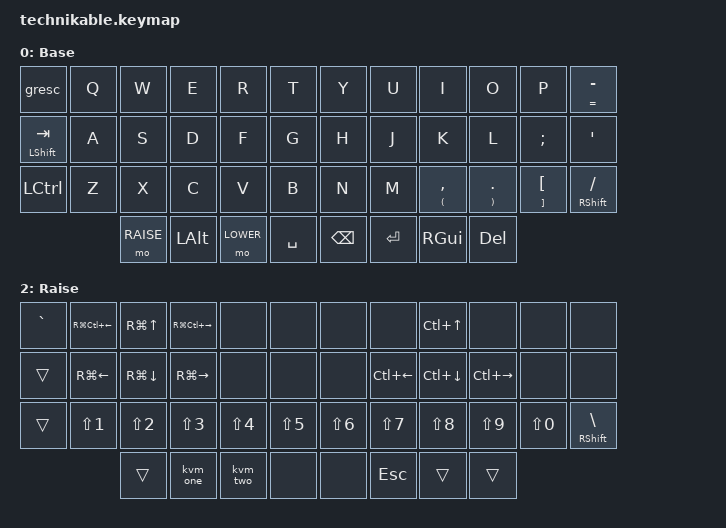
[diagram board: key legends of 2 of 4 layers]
/*
 * Copyright (c) 2022 Pete Johanson
 *
 * SPDX-License-Identifier: MIT
 */

 // build with 
 // west build -b technikable -DZMK_CONFIG="C:\Users\Nick\Documents\github\twiz-technikable"

#include <behaviors.dtsi>
#include <dt-bindings/zmk/keys.h>
#include <dt-bindings/zmk/bt.h>
#include <dt-bindings/zmk/outputs.h>


#define TBLE_ORTHO   true

#define BAS_L  0
#define LOWER  1
#define RAISE  2
#define ADJUST 3

// Using layer taps on thumbs, having quick tap as well helps w/ repeating space/backspace
&lt { quick_tap_ms = <200>; };
&mt { tapping-term-ms = <250>; };

#define BT(n) BT_SEL n

// MAJOR TAB HOLD KEYS
#define ES_TSK  &mt LS(LC(ESC)) ESC
#define COM_PR  &tp LPAR COMMA
#define DOT_PR  &tp RPAR DOT
#define SH_TAB  &tp LSHFT TAB // todo
#define SH_SLS  &tp RSHFT FSLH
#define SH_BSLS &tp RSHFT BSLH
#define ABRC    &tp RBKT LBKT //Brackets (ambidexterous)
#define PLS_MIN &tp EQUAL MINUS

// TAB MANAGEMENT
#define TAB_RES &kp LC(LS(T)) 
#define TABLF1  &mt F1 LC(LS(TAB)) 
#define TABRF3  &mt F3 LC(TAB) 
#define F5CF5   &mt F5 LC(F5)

// WINDOW AND VIRTUAL DESKTOP MANAGEMENT
#define SNAPUP  &kp RG(UP) 
#define SNAPLFT &kp RG(LEFT)
#define SNAPDN  &kp RG(DOWN) 
#define SNAPRGT &kp RG(RIGHT)
#define VDLFT   &kp RG(LC(LEFT)) 
#define VDRGT   &kp RG(LC(RIGHT)) 

// HOLD TAPS WITH NUMBERS AND USEFUL UTILITIES
#define DRK_1    &mt LA(LS(F)) N1  
#define VIS_3    &mt LA(LG(V)) N3 
#define AUDSRC_5 &mt LA(LC(LS(G))) N5  // 6 on tap, toggle audio source on hold
#define SSNIP    &kp LG(LS(S))  // GUI+SHIFT+S for snipping tool

// ADVANCED ALT TAB
/*
#define ALT_TAB &kp G  // todo// alt tab with timeout functionality
#define SHALTAB &kp G  // todo// when held: shift, when tapped: alt tab with timeout functionality
*/

#define MAXIMIZE &kp H // todo
#define AUDIOSRC &kp H // todo
#define PIK_WIN  &kp H // todo
#define VDTVIEW  &kp H // todo

#define TD_RD &kp G  // todo// macro for labelling in gmail
#define WT_SV &kp G  // todo// macro for labelling in gmail


/ {
    chosen {
       zmk,matrix_transform =
                       &ortho_transform;
    };

    conditional_layers {
        compatible = "zmk,conditional-layers";
        tri_layer {
            if-layers = <LOWER RAISE>;
            then-layer = <ADJUST>;
        };
    };
    behaviors {
        gresc: grave_escape {
            compatible = "zmk,behavior-mod-morph";
            label = "GRAVE_ESCAPE";
            #binding-cells = <0>;
            bindings = <ES_TSK>, <&kp GRAVE>;
            mods = <(MOD_RGUI|MOD_LSFT|MOD_LCTL|MOD_RSFT)>;
        };
        tp: tap-preferred {
            compatible = "zmk,behavior-hold-tap";
            label = "TAP_PREFERRED";
            #binding-cells = <2>;
            tapping-term-ms = <150>;
            quick-tap-ms = <0>;
            flavor = "tap-preferred";
            bindings = <&kp>, <&kp>;
        };
    };
    macros {
        link_paste: link_paste {
            label = "link_paste";
            compatible = "zmk,behavior-macro";
            #binding-cells = <0>;
            wait-ms = <50>;
            bindings
                = <&macro_press &kp LCTRL>
                , <&macro_tap &kp K>
                , <&macro_release &kp LCTRL>
                , <&macro_pause_for_release>
                , <&macro_press &kp LCTRL>
                , <&macro_tap &kp V>
                , <&macro_release &kp LCTRL>
                , <&macro_tap &kp ENTER>
                ;
        };
        //KVM SWITCHING
        kvm_one: kvm_one {
            label = "kvm_one";
            compatible = "zmk,behavior-macro";
            #binding-cells = <0>;
            wait-ms = <50>;
            bindings
                = <&macro_tap &kp SCROLLLOCK>
                , <&macro_tap &kp SCROLLLOCK>
                , <&macro_tap &kp N1>
                , <&macro_tap &kp ENTER>
                ;
        };
        kvm_two: kvm_two {
            label = "kvm_two";
            compatible = "zmk,behavior-macro";
            #binding-cells = <0>;
            wait-ms = <50>;
            bindings
                = <&macro_tap &kp SCROLLLOCK>
                , <&macro_tap &kp SCROLLLOCK>
                , <&macro_tap &kp N2>
                , <&macro_tap &kp ENTER>
                ;
        };
    };
    keymap {
        compatible = "zmk,keymap";

        base_layer {
            label = "Base";
            bindings = <
 &gresc      &kp Q      &kp W      &kp E       &kp R          &kp T          &kp Y            &kp U          &kp I       &kp O      &kp P         PLS_MIN
 SH_TAB      &kp A      &kp S      &kp D       &kp F          &kp G          &kp H            &kp J          &kp K       &kp L      &kp SEMI      &kp QUOT
 &kp LCTRL   &kp Z      &kp X      &kp C       &kp V          &kp B          &kp N            &kp M          COM_PR      DOT_PR     ABRC          SH_SLS
                        &mo RAISE  &kp LALT    &mo LOWER      &kp SPACE      &kp BSPC         &kp RET        &kp RGUI    &kp DEL
            >;
        };

        lower {
            label = "Lower";
            bindings = <
TAB_RES    TABLF1       &kp F2        TABRF3        &kp F4       F5CF5        &kp F6        &kp F7       &kp UP       &kp F9       &kp F10      &kp F11
&trans     &kp HOME     &kp PG_DN     &kp PG_UP     &kp END      SSNIP        &none         &kp LEFT     &kp DOWN     &kp RIGHT    &kp F8       &kp F12
&trans     DRK_1        &kp N2        VIS_3   &mt &link_paste N4 AUDSRC_5     &kp N6        &kp N7       &kp N8       &kp N9       &kp N0       SH_BSLS
                        &trans        &trans        &trans       &trans       &trans        &trans       &trans       &kp INS
           >;
        };

        raise {
            label = "Raise";
            bindings = <
&kp GRAVE  VDLFT      SNAPUP       VDRGT         &none          &none      &none         &none          &kp LC(UP)   &none         &none      &none 
&trans     SNAPLFT    SNAPDN       SNAPRGT       &none          &none      &none         &kp LC(LEFT)   &kp LC(DOWN) &kp LC(RIGHT) &none      &none 
&trans     &kp LS(N1) &kp LS(N2)   &kp LS(N3)    &kp LS(N4)     &kp LS(N5) &kp LS(N6)    &kp LS(N7)     &kp LS(N8)   &kp LS(N9)    &kp LS(N0) SH_BSLS
                      &trans       &kvm_one      &kvm_two       &none      &none         &kp ESC        &trans       &trans
            >;
        };

        adjust {
            label = "Adjust";
            bindings = <
&bt BT_CLR &trans     &trans     &trans      &trans          &trans       &trans     &trans         &trans      &trans     &trans     &kp DEL
&trans     &trans     &trans     &trans      &trans          &trans       &trans     &kp LARW       &kp DARW    &kp UARW   &kp RARW   &trans
&bt BT(0)  &bt BT(1)  &bt BT(2) &bt BT(3)    &bt BT(4)       &trans       &trans     &kp HOME       &kp PG_DN   &kp PG_UP  &kp END    SH_BSLS
                      &trans     &trans      &trans          &trans       &trans    &trans  &trans         &trans
            >;
        };

    };
};

